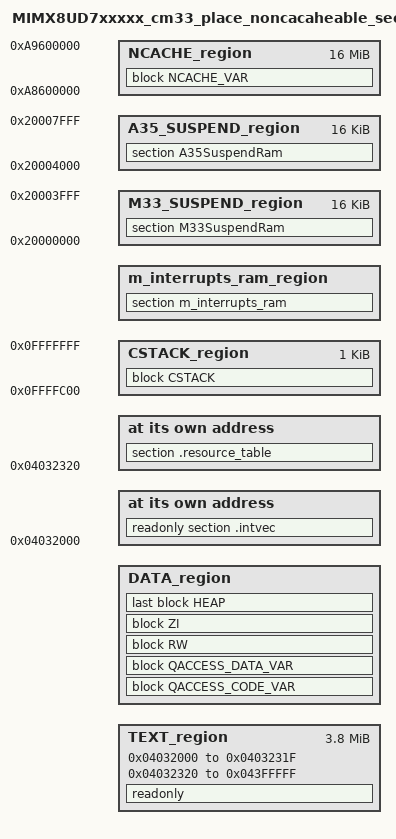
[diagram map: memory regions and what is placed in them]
/*
** ###################################################################
**     Processors:          MIMX8UD7DVK08_cm33
**                          MIMX8UD7DVP08_cm33
**
**     Compiler:            IAR ANSI C/C++ Compiler for ARM
**     Reference manual:    IMX8ULPRM, Rev. B, November. 2021
**     Version:             rev. 4.0, 2021-07-05
**     Build:               b211124
**
**     Abstract:
**         Linker file for the IAR ANSI C/C++ Compiler for ARM
**
**     Copyright 2016 Freescale Semiconductor, Inc.
**     Copyright 2016-2021 NXP
**     All rights reserved.
**
**     SPDX-License-Identifier: BSD-3-Clause
**
**     http:                 www.nxp.com
**     mail:                 support@nxp.com
**
** ###################################################################
*/

/* Memory region from [0x04000000-0x04000FFF] is reserved(1st Image Container Offset is 0x1000 = 4 KiB when boot device is FlexSPI NOR Flash) */
/*
 * Memory region from [0x04001000-0x04032000] is reserved for 1st Image Container and 2nd Image Container
 * - 1st Image Container: 1st container header + 1st signature block header + padding for 1 KiB alignment + sentinel firmware(maximum size = 128 KiB) = 2 KiB + 128 KiB = 130 KiB
 *
 * - 2nd Image Container: 2nd container header + 2nd signature block header + padding for 1 KiB alignment + upower firmware(maximum size = 64 KiB) = 2 KiB + 64 KiB = 66 KiB
 *
 * - flexspi0 start address = 0x4000000
 * entry point of m33 in flexspi0 nor flash = flexspi0 start address + 1st Image Container Offset + 1st Image Container size + 2nd Image Container size = 4 KiB + 130 KiB + 66 KiB = 200 KiB = 0x04032000
 * */
/* Memory region from [0x1FFC0000-0x1FFCFFFF] is reserved for shared memory between M33 and DSP. */
/* Memory region from [0x20008000-0x2002FFFF] is reserved for Fusion DSP */
/* Memory region from [0x20040000-0x2006FFFF] is reserved for A35 ATF */
/* Memory region from [0x20070000-0x2007FFFF] is reserved for ROM API and ROM boot */
/* Memory region(DDR) from [0xa8600000-0xa9600000](size = 16 MiB) is reserved for noncacheable data(such as: s_BufferLcd for lcd, s_asBufferPxp and s_psBufferPxp for pxp) */

define symbol __ram_vector_table_size__ =  isdefinedsymbol(__ram_vector_table__) ? 0x00000320 : 0;
define symbol __ram_vector_table_offset__ =  isdefinedsymbol(__ram_vector_table__) ? 0x0000031F : 0;

define symbol m_interrupts_start       = 0x04032000;
define symbol m_interrupts_end         = 0x0403231F;

define symbol m_text_start             = 0x04032320;
define symbol m_text_end               = 0x043FFFFF;

define symbol m_interrupts_ram_start   = 0x0FFD0000;
define symbol m_interrupts_ram_end     = 0x0FFD0000 + __ram_vector_table_offset__;

define symbol m_data_start             = m_interrupts_ram_start + __ram_vector_table_size__;
define symbol m_data_end               = 0x0FFFFFFF;

define symbol m_m33_suspend_ram_start  = 0x20000000;
define symbol m_m33_suspend_ram_end    = 0x20003FFF;

define symbol m_a35_suspend_ram_start  = 0x20004000;
define symbol m_a35_suspend_ram_end    = 0x20007FFF;

define symbol m_ncache_start           = 0xA8600000;
define symbol m_ncache_end             = 0xA9600000;

define exported symbol __NCACHE_REGION_START   = m_ncache_start;
define exported symbol __NCACHE_REGION_SIZE    = m_ncache_end - m_ncache_start + 1;
/* Sizes */
if (isdefinedsymbol(__stack_size__)) {
  define symbol __size_cstack__        = __stack_size__;
} else {
  define symbol __size_cstack__        = 0x0400;
}

if (isdefinedsymbol(__heap_size__)) {
  define symbol __size_heap__          = __heap_size__;
} else {
  define symbol __size_heap__          = 0x0400;
}

define exported symbol __VECTOR_TABLE  = m_interrupts_start;
define exported symbol __VECTOR_RAM    = isdefinedsymbol(__ram_vector_table__) ? m_interrupts_ram_start : m_interrupts_start;
define exported symbol __RAM_VECTOR_TABLE_SIZE = __ram_vector_table_size__;

define memory mem with size = 4G;
define region TEXT_region = mem:[from m_interrupts_start to m_interrupts_end]
                          | mem:[from m_text_start to m_text_end];
define region DATA_region = mem:[from m_data_start to m_data_end-__size_cstack__];
define region CSTACK_region = mem:[from m_data_end-__size_cstack__+1 to m_data_end];
define region m_interrupts_ram_region = mem:[from m_interrupts_ram_start to m_interrupts_ram_end];
define region M33_SUSPEND_region = mem:[from m_m33_suspend_ram_start to m_m33_suspend_ram_end];
define region A35_SUSPEND_region = mem:[from m_a35_suspend_ram_start to m_a35_suspend_ram_end];
define region NCACHE_region = mem:[from m_ncache_start to m_ncache_end];

define block CSTACK    with alignment = 8, size = __size_cstack__   { };
define block HEAP      with alignment = 8, size = __size_heap__     { };
define block RW        { readwrite };
define block ZI        { zi };
define block NCACHE_VAR    { section NonCacheable , section NonCacheable.init };
define block QACCESS_CODE_VAR   with alignment = 32 { section CodeQuickAccess };
define block QACCESS_DATA_VAR   with alignment = 32 { section DataQuickAccess };

initialize by copy { readwrite, section .textrw, section CodeQuickAccess, section DataQuickAccess };
do not initialize  { section .noinit, section M33SuspendRam, section A35SuspendRam, section NonCacheable };

keep{section .resource_table};

place at address mem: m_interrupts_start    { readonly section .intvec };
".resource_table": place at address mem: m_text_start {section .resource_table};
place in TEXT_region                        { readonly };
place in DATA_region                        { block QACCESS_CODE_VAR };
place in DATA_region                        { block QACCESS_DATA_VAR };
place in DATA_region                        { block RW };
place in DATA_region                        { block ZI };
place in DATA_region                        { last block HEAP };
place in CSTACK_region                      { block CSTACK };
place in m_interrupts_ram_region            { section m_interrupts_ram };
place in M33_SUSPEND_region                 { section M33SuspendRam };
place in A35_SUSPEND_region                 { section A35SuspendRam };
place in NCACHE_region                      { block NCACHE_VAR };
